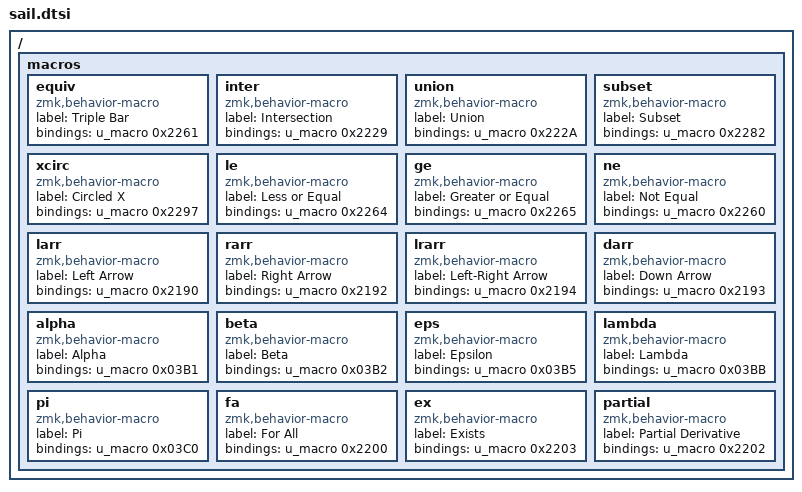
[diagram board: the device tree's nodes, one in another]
/*
 * Special characters for the SAIL keycaps
 */

#include <behaviors/unicode.dtsi>

/ {
	macros {
		// SAIL Layer Unicode Symbols using zmk-unicode module
		equiv: equiv {
			label = "Triple Bar";
			compatible = "zmk,behavior-macro";
			#binding-cells = <0>;
			bindings = <&u_macro 0x2261>;
		};
		inter: inter {
			label = "Intersection";
			compatible = "zmk,behavior-macro";
			#binding-cells = <0>;
			bindings = <&u_macro 0x2229>;
		};
		union: union {
			label = "Union";
			compatible = "zmk,behavior-macro";
			#binding-cells = <0>;
			bindings = <&u_macro 0x222A>;
		};
		subset: subset {
			label = "Subset";
			compatible = "zmk,behavior-macro";
			#binding-cells = <0>;
			bindings = <&u_macro 0x2282>;
		};
		xcirc: xcirc {
			label = "Circled X";
			compatible = "zmk,behavior-macro";
			#binding-cells = <0>;
			bindings = <&u_macro 0x2297>;
		};
		le: le {
			label = "Less or Equal";
			compatible = "zmk,behavior-macro";
			#binding-cells = <0>;
			bindings = <&u_macro 0x2264>;
		};
		ge: ge {
			label = "Greater or Equal";
			compatible = "zmk,behavior-macro";
			#binding-cells = <0>;
			bindings = <&u_macro 0x2265>;
		};
		ne: ne {
			label = "Not Equal";
			compatible = "zmk,behavior-macro";
			#binding-cells = <0>;
			bindings = <&u_macro 0x2260>;
		};
		larr: larr {
			label = "Left Arrow";
			compatible = "zmk,behavior-macro";
			#binding-cells = <0>;
			bindings = <&u_macro 0x2190>;
		};
		rarr: rarr {
			label = "Right Arrow";
			compatible = "zmk,behavior-macro";
			#binding-cells = <0>;
			bindings = <&u_macro 0x2192>;
		};
		lrarr: lrarr {
			label = "Left-Right Arrow";
			compatible = "zmk,behavior-macro";
			#binding-cells = <0>;
			bindings = <&u_macro 0x2194>;
		};
		darr: darr {
			label = "Down Arrow";
			compatible = "zmk,behavior-macro";
			#binding-cells = <0>;
			bindings = <&u_macro 0x2193>;
		};
		alpha: alpha {
			label = "Alpha";
			compatible = "zmk,behavior-macro";
			#binding-cells = <0>;
			bindings = <&u_macro 0x03B1>;
		};
		beta: beta {
			label = "Beta";
			compatible = "zmk,behavior-macro";
			#binding-cells = <0>;
			bindings = <&u_macro 0x03B2>;
		};
		eps: eps {
			label = "Epsilon";
			compatible = "zmk,behavior-macro";
			#binding-cells = <0>;
			bindings = <&u_macro 0x03B5>;
		};
		lambda: lambda {
			label = "Lambda";
			compatible = "zmk,behavior-macro";
			#binding-cells = <0>;
			bindings = <&u_macro 0x03BB>;
		};
		pi: pi {
			label = "Pi";
			compatible = "zmk,behavior-macro";
			#binding-cells = <0>;
			bindings = <&u_macro 0x03C0>;
		};
		fa: fa {
			label = "For All";
			compatible = "zmk,behavior-macro";
			#binding-cells = <0>;
			bindings = <&u_macro 0x2200>;
		};
		ex: ex {
			label = "Exists";
			compatible = "zmk,behavior-macro";
			#binding-cells = <0>;
			bindings = <&u_macro 0x2203>;
		};
		partial: partial {
			label = "Partial Derivative";
			compatible = "zmk,behavior-macro";
			#binding-cells = <0>;
			bindings = <&u_macro 0x2202>;
		};
	};
};
